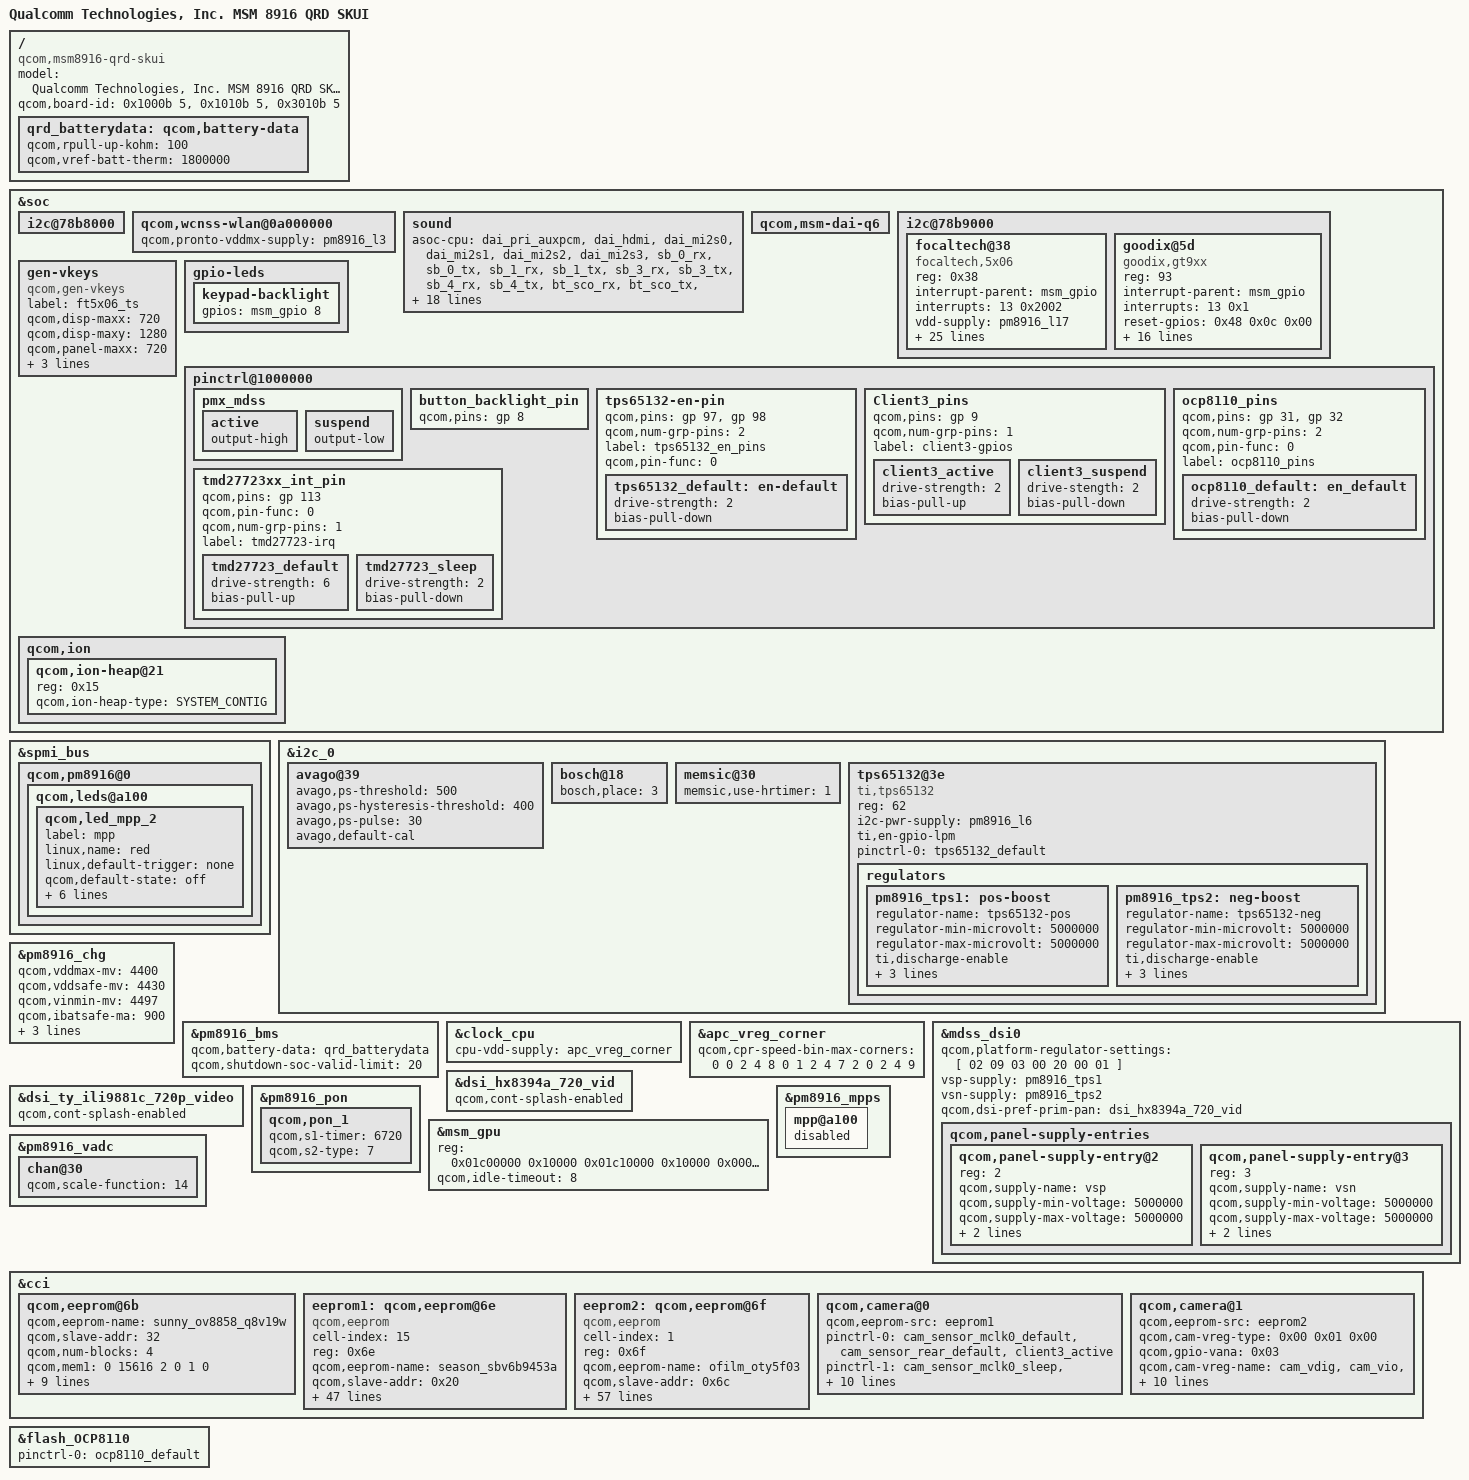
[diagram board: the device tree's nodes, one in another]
/* Copyright (c) 2014, The Linux Foundation. All rights reserved.
 *
 * This program is free software; you can redistribute it and/or modify
 * it under the terms of the GNU General Public License version 2 and
 * only version 2 as published by the Free Software Foundation.
 *
 * This program is distributed in the hope that it will be useful,
 * but WITHOUT ANY WARRANTY; without even the implied warranty of
 * MERCHANTABILITY or FITNESS FOR A PARTICULAR PURPOSE.  See the
 * GNU General Public License for more details.
 */

/dts-v1/;

#include "msm8916-qrd-skui.dtsi"
#include "msm8916-memory.dtsi"
#include "dsi-panel-ty-hx8394f-720p-video.dtsi"
#include "dsi-panel-ty-ili9881c-720p-video.dtsi"

/ {
	model = "Qualcomm Technologies, Inc. MSM 8916 QRD SKUI";
	compatible = "qcom,msm8916-qrd-skui", "qcom,msm8916-qrd", "qcom,msm8916", "qcom,qrd";
	qcom,board-id = <0x1000b 5> , <0x1010b 5> , <0x3010b 5>;
};

&soc {
	i2c@78b8000 {
/*		smb1360_otg_supply: smb1360-chg-fg@14 {
			compatible = "qcom,smb1360-chg-fg";
			reg = <0x14>;
			interrupt-parent = <&msm_gpio>;
			interrupts = <62 8>;
			pinctrl-names = "default";
			pinctrl-0 = <&smb_int_default>;
			qcom,chg-inhibit-disabled;
			qcom,float-voltage-mv = <4350>;
			qcom,iterm-ma = <200>;
			qcom,recharge-thresh-mv = <100>;
			qcom,thermal-mitigation = <1500 700 600 0>;
			qcom,fg-auto-recharge-soc = <99>;
			regulator-name = "smb1360_otg_vreg";
		};*/
	};

	qcom,wcnss-wlan@0a000000 {
		qcom,pronto-vddmx-supply = <&pm8916_l3>;
	};

	sound {
		asoc-cpu = <&dai_pri_auxpcm>, <&dai_hdmi>,
				<&dai_mi2s0>, <&dai_mi2s1>, <&dai_mi2s2>, <&dai_mi2s3>,
				<&sb_0_rx>, <&sb_0_tx>, <&sb_1_rx>, <&sb_1_tx>,
				<&sb_3_rx>, <&sb_3_tx>, <&sb_4_rx>, <&sb_4_tx>,
				<&bt_sco_rx>, <&bt_sco_tx>,
				<&int_fm_rx>, <&int_fm_tx>,
				<&afe_pcm_rx>, <&afe_pcm_tx>, <&afe_proxy_rx>, <&afe_proxy_tx>,
				<&incall_record_rx>, <&incall_record_tx>, <&incall_music_rx>, <&incall_music_2_rx>;

		asoc-cpu-names = "msm-dai-q6-auxpcm.1", "msm-dai-q6-hdmi.8",
			"msm-dai-q6-mi2s.0", "msm-dai-q6-mi2s.1",
			"msm-dai-q6-mi2s.2", "msm-dai-q6-mi2s.3",
			"msm-dai-q6-dev.16384", "msm-dai-q6-dev.16385",
			"msm-dai-q6-dev.16386", "msm-dai-q6-dev.16387",
			"msm-dai-q6-dev.16390", "msm-dai-q6-dev.16391",
			"msm-dai-q6-dev.16392", "msm-dai-q6-dev.16393",
			"msm-dai-q6-dev.12288", "msm-dai-q6-dev.12289",
			"msm-dai-q6-dev.12292",	"msm-dai-q6-dev.12293",
			"msm-dai-q6-dev.224",	"msm-dai-q6-dev.225",
			"msm-dai-q6-dev.241",	"msm-dai-q6-dev.240",
			"msm-dai-q6-dev.32771",	"msm-dai-q6-dev.32772",
			"msm-dai-q6-dev.32773",	"msm-dai-q6-dev.32770";
	};

	qcom,msm-dai-q6 {
		/delete-property/ bt_a2dp_rx;
	};

	i2c@78b9000 { /* BLSP1 QUP5 */
		focaltech@38 {
			compatible = "focaltech,5x06";
			reg = <0x38>;
			interrupt-parent = <&msm_gpio>;
			interrupts = <13 0x2002>;
			vdd-supply = <&pm8916_l17>;
			vcc_i2c-supply = <&pm8916_l6>;
			/* pins used by touchscreen */
			pinctrl-names = "pmx_ts_active","pmx_ts_suspend","pmx_ts_release";
			pinctrl-0 = <&ts_int_active &ts_reset_active>;
			pinctrl-1 = <&ts_int_suspend &ts_reset_suspend>;
			pinctrl-2 = <&ts_release>;
			focaltech,name = "ft5336";
			focaltech,family-id = <0x14>;
			focaltech,reset-gpio = <&msm_gpio 12 0x0>;
			focaltech,irq-gpio = <&msm_gpio 13 0x2002>;
			focaltech,display-coords = <0 0 720 1280>;
			focaltech,panel-coords = <0 0 720 1424>;
			focaltech,button-map= <139 102 158>;
			focaltech,no-force-update;
			focaltech,i2c-pull-up;
			focaltech,group-id = <1>;
			focaltech,hard-reset-delay-ms = <20>;
			focaltech,soft-reset-delay-ms = <200>;
			focaltech,num-max-touches = <5>;
			focaltech,fw-delay-aa-ms = <30>;
			focaltech,fw-delay-55-ms = <30>;
			focaltech,fw-upgrade-id1 = <0x79>;
			focaltech,fw-upgrade-id2 = <0x11>;
			focaltech,fw-delay-readid-ms = <10>;
			focaltech,fw-delay-era-flsh-ms = <2000>;
			focaltech,fw-auto-cal;
			focaltech,ignore-id-check;
		};

		goodix@5d {
			compatible = "goodix,gt9xx";
			reg = <93>;
			interrupt-parent = <&msm_gpio>;
			interrupts = <13 0x1>;
			reset-gpios = < 0x48 0x0c 0x00 >;
			interrupt-gpios = < 0x48 0x0d 0x00 >;
			vdd-supply = <&pm8916_l17>;
			vdd-io-supply = <&pm8916_l16>;
			vcc_i2c-supply = <&pm8916_l6>;
			goodix,i2c-pull-up;
			goodix,panel-coords = <0 0 720 1400>;
			goodix,display-coords = <0 0 720 1280>;
			goodix,button-map= <158 102 139>;
			goodix,vir-button-codes = <139 90 1340 100 80 172 360 1340 100 80 158 630 1340 100 80>;
			goodix,family-id = <0>;
			goodix,cfg-count = <2 0 2 0 0 0 0>;
			goodix,cfg-data0 = [ 41 d0 02 00 05 05 35 01 01 0f 28 05 50 32 03 05 00 00 00 00 00 00 00 17 19 1f 14 8c 2e 0e 44 42 d4 07 00 00 00 5b 02 11 00 00 00 00 00 00 00 08 0a 00 00 32 64 94 c5 02 07 00 00 04 94 35 00 86 3d 00 7b 46 00 71 51 00 69 5d 00 69 18 40 60 00 f0 4a 3a ff ff 27 00 00 00 00 00 00 00 00 00 00 00 00 00 00 00 00 00 00 00 00 00 00 00 00 00 00 02 04 06 08 0a 0c 0e 10 12 14 16 18 1a 1c 00 00 00 00 00 00 00 00 00 00 00 00 00 00 00 00 00 02 04 06 08 0a 0c 0f 10 12 13 14 16 18 1c 1d 1e 1f 20 21 22 24 26 28 29 2a 00 00 00 00 00 00 00 00 00 00 00 00 00 00 00 00 2f 01 ];
			goodix,cfg-data2 = [ 41 d0 02 00 05 05 35 01 01 08 28 05 50 32 03 05 00 00 00 00 00 00 00 17 19 1e 14 8c 2c 0d 44 42 d4 07 00 00 01 42 02 11 00 00 00 00 00 00 00 08 0a 00 00 32 64 94 c5 02 07 00 00 04 96 35 00 87 3d 00 7a 46 00 6f 51 00 67 5d 00 67 18 38 58 00 f0 4a 3a ff ff 27 00 00 00 00 00 00 00 00 00 00 00 00 00 00 00 00 00 00 00 00 00 00 00 00 00 00 02 04 06 08 0a 0c 0e 10 12 14 16 18 1a ff 00 00 00 00 00 00 00 00 00 00 00 00 00 00 00 00 16 18 1c 1d 1e 1f 20 21 22 24 26 28 14 13 12 10 0f 0c 0a 08 06 04 02 00 ff ff 00 00 00 00 00 00 00 00 00 00 00 00 00 00 00 00 d8 01 ];
		};
	};

	gen-vkeys {
		compatible = "qcom,gen-vkeys";
		label = "ft5x06_ts";
		qcom,disp-maxx = <720>;
		qcom,disp-maxy = <1280>;
		qcom,panel-maxx = <720>;
		qcom,panel-maxy = <1424>;
		qcom,key-codes = <139 172 158>;
		qcom,y-offset = <0>;
	};

	gpio-leds {
		keypad-backlight {
			gpios = <&msm_gpio 8 0>;
		};
	};

	pinctrl@1000000 {
		pmx_mdss {
			active {
				output-high;
			};

			suspend {
				output-low;
			};
		};

		button_backlight_pin {
			qcom,pins = <&gp 8>;
		};

		tps65132-en-pin {
			qcom,pins = <&gp 97>, <&gp 98>;
			qcom,num-grp-pins = <2>;
			label = "tps65132_en_pins";
			qcom,pin-func = <0>;

			tps65132_default: en-default {
				drive-strength = <2>;
				bias-pull-down;
			};
		};

		Client3_pins {
			qcom,pins = <&gp 9>;
			qcom,num-grp-pins = <1>;
			label = "client3-gpios";

			client3_active: client3_active {
				drive-strength = <2>;
				bias-pull-up;
			};

			client3_suspend: client3_suspend {
				drive-stength = <2>;
				bias-pull-down;
			};
		};

		ocp8110_pins {
			qcom,pins = <&gp 31>, <&gp 32>;
			qcom,num-grp-pins = <2>;
			qcom,pin-func = <0>;
			label = "ocp8110_pins";

			ocp8110_default: en_default {
				drive-strength = <2>;
				bias-pull-down;
			};
		};

		tmd27723xx_int_pin {
			qcom,pins = <&gp 113>;
			qcom,pin-func = <0>;
			qcom,num-grp-pins = <1>;
			label = "tmd27723-irq";

			tmd27723_default {
				drive-strength = <6>;
				bias-pull-up;
			};

			tmd27723_sleep {
				drive-strength = <2>;
				bias-pull-down;
			};
		};
	};

	qcom,ion {
		qcom,ion-heap@21 {
			reg = < 0x15 >;
			qcom,ion-heap-type = "SYSTEM_CONTIG";
		};
	};
};

&spmi_bus {
	qcom,pm8916@0 {
		qcom,leds@a100 {
			status = "okay";
			qcom,led_mpp_2 {
				label = "mpp";
				linux,name = "red";
				linux,default-trigger = "none";
				qcom,default-state = "off";
				qcom,max-current = <40>;
				qcom,current-setting = <5>;
				qcom,id = <6>;
				qcom,mode = "manual";
				qcom,source-sel = <1>;
				qcom,mode-ctrl = <0x60>;
			};
		};
	};
};

&i2c_0 { /* BLSP1 QUP2 */
	avago@39 {
		avago,ps-threshold = <500>;
		avago,ps-hysteresis-threshold = <400>;
		avago,ps-pulse = <30>;
		avago,default-cal;
	};

	bosch@18 {
		bosch,place = <3>;
	};

	memsic@30 {
		memsic,use-hrtimer = <1>;
	};

	tps65132@3e {
		compatible = "ti,tps65132";
		reg = <62>;
		i2c-pwr-supply = <&pm8916_l6>;
		ti,en-gpio-lpm;
		pinctrl-names = "default";
		pinctrl-0 = <&tps65132_default>;

		regulators {
			pm8916_tps1: pos-boost {
				regulator-name = "tps65132-pos";
				regulator-min-microvolt = <5000000>;
				regulator-max-microvolt = <5000000>;
				ti,discharge-enable;
				ti,enable-time = <800>;
				ti,current-limit = <200000>;
				ti,en-gpio = <&msm_gpio 97 0>;
			};

			pm8916_tps2: neg-boost {
				regulator-name = "tps65132-neg";
				regulator-min-microvolt = <5000000>;
				regulator-max-microvolt = <5000000>;
				ti,discharge-enable;
				ti,enable-time = <800>;
				ti,current-limit = <40000>;
				ti,en-gpio = <&msm_gpio 98 0>;
			};
		};
	};
};

/delete-node/ &kgsl_drm;

&pm8916_chg {
	status = "ok";
	qcom,vddmax-mv = <4400>;
	qcom,vddsafe-mv = <4430>;
	qcom,vinmin-mv = <4497>;
	qcom,ibatsafe-ma = <900>;
	qcom,thermal-mitigation = <990 720 630 0>;
	qcom,tchg-mins = <480>;
	qcom,fcc-mah = <2920>;
};

/ {
	qrd_batterydata: qcom,battery-data {
		qcom,rpull-up-kohm = <100>;
		qcom,vref-batt-therm = <1800000>;
		#include "batterydata-qrd-ty-4v4-2920mah.dtsi"
		#include "batterydata-qrd-ty-atl-4v4-2920mah.dtsi"
	};
};


&pm8916_bms {
	status = "ok";
	qcom,battery-data = <&qrd_batterydata>;
	qcom,shutdown-soc-valid-limit = <20>;
};

/*&usb_otg {
	qcom,hsusb-otg-mode = <3>;
	qcom,usbid-gpio = <&msm_gpio 110 0>;
	pinctrl-names = "default";
	pinctrl-0 = <&usbid_default>;
	vbus_otg-supply = <&smb1360_otg_supply>;
};*/

&clock_cpu {
	/delete-property/ qcom,speed3-bin-v0;
	/delete-property/ qcom,speed3-bin-v1;
	cpu-vdd-supply = <&apc_vreg_corner>;
};

&apc_vreg_corner {
	qcom,cpr-speed-bin-max-corners = <0 0 2 4 8 0 1 2 4 7 2 0 2 4 9>;
};

&mdss_dsi0 {
	qcom,platform-regulator-settings = [ 02 09 03 00 20 00 01 ];
	vsp-supply = <&pm8916_tps1>;
	vsn-supply = <&pm8916_tps2>;
	qcom,dsi-pref-prim-pan = <&dsi_hx8394a_720_vid>;
	qcom,panel-supply-entries {
		qcom,panel-supply-entry@2 {
		       reg = <2>;
		       qcom,supply-name = "vsp";
		       qcom,supply-min-voltage = <5000000>;
		       qcom,supply-max-voltage = <5000000>;
		       qcom,supply-enable-load = <200>;
		       qcom,supply-disable-load = <0>;
		};

		qcom,panel-supply-entry@3 {
			reg = <3>;
			qcom,supply-name = "vsn";
			qcom,supply-min-voltage = <5000000>;
			qcom,supply-max-voltage = <5000000>;
			qcom,supply-enable-load = <40>;
			qcom,supply-disable-load = <0>;
	       };
       };
};

&dsi_hx8394a_720_vid {
	qcom,cont-splash-enabled;
};

&dsi_ty_ili9881c_720p_video {
	qcom,cont-splash-enabled;
};

&pm8916_pon {
	qcom,pon_1 {
		qcom,s1-timer = <6720>;
		qcom,s2-type = <7>;
	};
};

&msm_gpu {
	reg = <0x01c00000 0x10000
	       0x01c10000 0x10000
	       0x0005c00c 8>;
	reg-names = "kgsl_3d0_reg_memory" , "kgsl_3d0_shader_memory" ,
			    "efuse_memory";
	qcom,idle-timeout = <8>;
};

&pm8916_vadc {
	chan@30 {
		qcom,scale-function = <14>;
	};
};

&pm8916_mpps {
	mpp@a100 {
		status = "disabled";
	};
};

&cci {
	qcom,eeprom@6b {
		qcom,eeprom-name = "sunny_ov8858_q8v19w";
		qcom,slave-addr = <32>;
		qcom,num-blocks = <4>;
		qcom,mem1 = <0 15616 2 0 1 0>;
		qcom,page2 = <1 15752 2 28688 2 1>;
		qcom,mem2 = <0 15616 2 0 1 0>;
		qcom,page3 = <1 15754 2 29060 2 1>;
		qcom,mem3 = <373 28688 2 0 1 1>;
		qcom,cam-vreg-min-voltage = <1200000 0 2800000 2850000>;
		qcom,cam-vreg-max-voltage = <1200000 0 2850000 2900000>;
		qcom,cam-vreg-type = <0 1 0 0>;
	};

	eeprom1: qcom,eeprom@6e{
		cell-index = <15>;
		reg = <0x6e>;
		qcom,eeprom-name = "season_sbv6b9453a";
		compatible = "qcom,eeprom";
		qcom,slave-addr = <0x20>;
		qcom,cci-master = <0>;
		qcom,num-blocks = <4>;

		qcom,page0 = <1 0x0100 2 0x01 1 1>;
		qcom,poll0 = <0 0x0 2 0 1 1>;
		qcom,mem0 = <0 0x0 2 0 1 0>;
		qcom,page1 = <1 0x3d84 2 0xc0 1 1>;
		qcom,poll1 = <0 0x0 2 0 1 1>;
		qcom,mem1 = <0 0x3d00 2 0 1 0>;
		qcom,page2 = <1 0x3d88 2 0x7010 2 1>;
		qcom,poll2 = <0 0x0 2 0 1 1>;
		qcom,mem2 = <0 0x3d00 2 0 1 0>;
		qcom,page3 = <1 0x3d8a 2 0x7184 2 1>;
		qcom,pageen3 = <1 0x3d81 2 0x01 1 10>;
		qcom,poll3 = <0 0x0 2 0 1 1>;
		qcom,mem3 = <373 0x7010 2 0 1 1>;
		cam_vdig-supply = <&pm8916_l2>;
		cam_vana-supply = <&pm8916_l17>;
		cam_vio-supply = <&pm8916_l6>;
		cam_vaf-supply = <&pm8916_l10>;
		qcom,cam-vreg-name = "cam_vdig", "cam_vio", "cam_vana",
							"cam_vaf";
		qcom,cam-vreg-type = < 0x00 0x01 0x00 0x00 >;
		qcom,cam-vreg-min-voltage = <1200000 0 2800000 2850000>;
		qcom,cam-vreg-max-voltage = <1200000 0 2850000 2900000>;
		qcom,cam-vreg-op-mode = <200000 0 80000 100000>;
		pinctrl-names = "cam_default", "cam_suspend";
		pinctrl-0 = <&cam_sensor_mclk0_default &cam_sensor_rear_default>;
		pinctrl-1 = <&cam_sensor_mclk0_sleep &cam_sensor_rear_sleep>;
		gpios = <&msm_gpio 26 0>,
			<&msm_gpio 35 0>,
			<&msm_gpio 34 0>;
		qcom,gpio-reset = <1>;
		qcom,gpio-standby = <2>;
		qcom,gpio-req-tbl-num = <0 1 2 >;
		qcom,gpio-req-tbl-flags = <1 0 0>;
		qcom,gpio-req-tbl-label = "CAMIF_MCLK",
			"CAM_RESET1",
			"CAM_STANDBY";

		qcom,cam-power-seq-type = "sensor_vreg",
			"sensor_gpio", "sensor_gpio",
			"sensor_clk";
		qcom,cam-power-seq-val = "cam_vaf",
			"sensor_gpio_reset",
			"sensor_gpio_standby",
			"sensor_cam_mclk" ;
		qcom,cam-power-seq-cfg-val = <1 1 1 23880000>;
		qcom,cam-power-seq-delay = <1 10 10 5>;

		clocks = <&clock_gcc clk_mclk0_clk_src>,
			<&clock_gcc clk_gcc_camss_mclk0_clk>;
		clock-names = "cam_src_clk", "cam_clk";
	};

	eeprom2: qcom,eeprom@6f{
		cell-index = <1>;
		reg = <0x6f>;
		qcom,eeprom-name = "ofilm_oty5f03";
		compatible = "qcom,eeprom";
		qcom,slave-addr = <0x6c>;
		qcom,cci-master = <0>;
		qcom,num-blocks = <9>;

		qcom,page0 = <1 0x0100 2 0x01 1 1>;
		qcom,poll0 = <0 0x0 2 0 1 1>;
		qcom,mem0 = <0 0x0 2 0 1 0>;
		qcom,page1 = <1 0x3d84 2 0xc0 1 1>;
		qcom,poll1 = <0 0x0 2 0 1 1>;
		qcom,mem1 = <0 0x0 2 0 1 0>;
		qcom,page2 = <1 0x3d85 2 0x00 1 1>;
		qcom,poll2 = <0 0x0 2 0 1 1>;
		qcom,mem2 = <0 0x0 2 0 1 1>;
		qcom,page3 = <1 0x3d86 2 0x0f 1 1>;
		qcom,poll3 = <0 0x0 2 0 1 1>;
		qcom,mem3 = <0 0 2 0 1 1>;
		qcom,page4 = <1 0x3d81 2 1 1 1>;
		qcom,poll4 = <0 0x0 2 0 1 1>;
		qcom,mem4 = < 0x0f 0x3d00 0x02 0x00 0x01 0x00 >;
		qcom,page5 = < 0x01 0x3d84 0x02 0xc0 0x01 0x01 >;
		qcom,poll5 = < 0x00 0x00 0x02 0x00 0x01 0x01 >;
		qcom,mem5 = < 0x00 0x00 0x02 0x00 0x01 0x01 >;
		qcom,page6 = < 0x01 0x3d85 0x02 0x10 0x01 0x01 >;
		qcom,poll6 = < 0x00 0x00 0x02 0x00 0x01 0x01 >;
		qcom,mem6 = < 0x00 0x00 0x02 0x00 0x01 0x01 >;
		qcom,page7 = < 0x01 0x3d86 0x02 0x1f 0x01 0x01 >;
		qcom,poll7 = < 0x00 0x00 0x02 0x00 0x01 0x01 >;
		qcom,mem7 = < 0x00 0x00 0x02 0x00 0x01 0x00 >;
		qcom,page8 = < 0x01 0x3d81 0x02 0x01 0x01 0x01 >;
		qcom,poll8 = < 0x00 0x00 0x02 0x00 0x01 0x01 >;
		qcom,mem8 = < 0x0f 0x3d00 0x02 0x00 0x01 0x00 >;
		cam_vdig-supply = <&pm8916_l2>;
		cam_vana-supply = <&pm8916_l17>;
		cam_vio-supply = <&pm8916_l6>;
		qcom,cam-vreg-name = "cam_vdig", "cam_vio", "cam_vana";
		qcom,cam-vreg-type = <0 1 0>;
		qcom,cam-vreg-min-voltage = <1200000 0 2850000>;
		qcom,cam-vreg-max-voltage = <1200000 0 2850000>;
		qcom,cam-vreg-op-mode = <200000 0 80000>;
		pinctrl-names = "cam_default", "cam_suspend";
		pinctrl-0 = <&cam_sensor_mclk1_default &cam_sensor_front_default>;
		pinctrl-1 = <&cam_sensor_mclk1_sleep &cam_sensor_front_sleep>;
		gpios = <&msm_gpio 27 0>,
			<&msm_gpio 28 0>,
			<&msm_gpio 33 0>;
		qcom,gpio-reset = <1>;
		qcom,gpio-standby = <2>;
		qcom,gpio-req-tbl-num = <0 1 2 >;
		qcom,gpio-req-tbl-flags = <1 0 0>;
		qcom,gpio-req-tbl-label = "CAMIF_MCLK",
			"SCAM_RESET",
			"SCAM_STANDBY";

		qcom,cam-power-seq-type = "sensor_gpio", "sensor_gpio",
			"sensor_clk";
		qcom,cam-power-seq-val = "sensor_gpio_standby",
			"sensor_gpio_reset",
			"sensor_cam_mclk" ;
		qcom,cam-power-seq-cfg-val = <1 1 23880000>;
		qcom,cam-power-seq-delay = <5 10 10>;

		clocks = <&clock_gcc clk_mclk1_clk_src>,
			<&clock_gcc clk_gcc_camss_mclk1_clk>;
		clock-names = "cam_src_clk", "cam_clk";
	};

	qcom,camera@0 {
		qcom,eeprom-src = <&eeprom1>;
		pinctrl-0 = <&cam_sensor_mclk0_default &cam_sensor_rear_default &client3_active>;
		pinctrl-1 = <&cam_sensor_mclk0_sleep &cam_sensor_rear_sleep &client3_suspend>;
		gpios = <&msm_gpio 26 0>,
			<&msm_gpio 35 0>,
			<&msm_gpio 34 0>,
			<&msm_gpio 120 0>,
			<&msm_gpio 9 0>,
			<&msm_gpio 20 0>;
		qcom,gpio-req-tbl-num = <0 1 2 3 4 5>;
		qcom,gpio-req-tbl-flags = <1 0 0 0 0 0>;
		qcom,gpio-req-tbl-label = "CAMIF_MCLK",
			"CAM_RESET1",
			"CAM_STANDBY",
			"CAM_AF_PWDM",
			"CAM_ID",
			"CAM_VANA";
		qcom,gpio-camid = < 0x04 >;
		qcom,gpio-vana = < 0x05 >;
	};

	qcom,camera@1 {
		qcom,eeprom-src = <&eeprom2>;
		qcom,cam-vreg-type = < 0x00 0x01 0x00>;
		qcom,gpio-vana = < 0x03 >;
		qcom,cam-vreg-name = "cam_vdig", "cam_vio", "cam_vana";
		qcom,cam-vreg-min-voltage = <1200000 0 2850000>;
		qcom,cam-vreg-max-voltage = <1200000 0 2850000>;
		qcom,cam-vreg-op-mode = <200000 0 80000>;
		gpios = <&msm_gpio 27 0>,
			<&msm_gpio 28 0>,
			<&msm_gpio 33 0>,
			<&msm_gpio 20 0 >;
		qcom,gpio-req-tbl-num = <0 1 2 3>;
		qcom,gpio-req-tbl-flags = <1 0 0 0 >;
		qcom,gpio-req-tbl-label = "CAMIF_MCLK",
			"CAM_RESET",
			"CAM_STANDBY",
			"CAM_VANA";
	};
};

&flash_OCP8110 {
	pinctrl-0 = <&ocp8110_default>;
};
